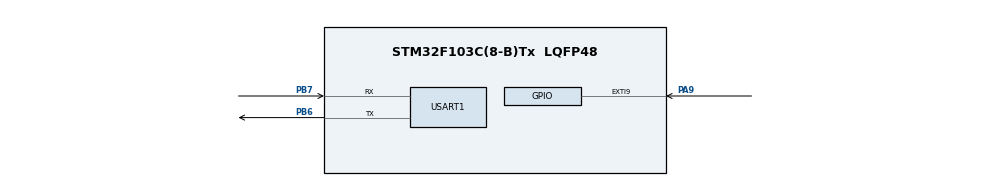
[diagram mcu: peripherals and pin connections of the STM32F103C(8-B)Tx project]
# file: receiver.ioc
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Mcu.Family=STM32F1
Mcu.Name=STM32F103C(8-B)Tx
Mcu.Package=LQFP48
NVIC.EXTI9_5_IRQn=true\:0\:0\:false\:false\:true\:true\:true\:true
NVIC.PriorityGroup=NVIC_PRIORITYGROUP_4
NVIC.TIM2_IRQn=true\:0\:0\:false\:false\:true\:true\:true\:true
PA13.Mode=Serial_Wire
PA13.Signal=SYS_JTMS-SWDIO
PA14.Mode=Serial_Wire
PA14.Signal=SYS_JTCK-SWCLK
PA9.GPIO_PuPd=GPIO_PULLUP
PA9.Signal=GPXTI9
PB6.Mode=Asynchronous
PB6.Signal=USART1_TX
PB7.Mode=Asynchronous
PB7.Signal=USART1_RX
ProjectManager.HeapSize=0x200
ProjectManager.StackSize=0x400
ProjectManager.TargetToolchain=MDK-ARM V5.32
RCC.APB1Freq_Value=8000000
RCC.APB2Freq_Value=8000000
TIM2.AutoReloadPreload=TIM_AUTORELOAD_PRELOAD_ENABLE
TIM2.Period=70-1
USART1.VirtualMode=VM_ASYNC
VP_TIM2_VS_ClockSourceINT.Mode=Internal
board=custom

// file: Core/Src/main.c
/* USER CODE BEGIN Header */
/**
  ******************************************************************************
  * @file           : main.c
  * @brief          : Main program body
  ******************************************************************************
  * @attention
  *
  * Copyright (c) 2025 STMicroelectronics.
  * All rights reserved.
  *
  * This software is licensed under terms that can be found in the LICENSE file
  * in the root directory of this software component.
  * If no LICENSE file comes with this software, it is provided AS-IS.
  *
  ******************************************************************************
  */
/* USER CODE END Header */
#include "main.h"

/* USER CODE BEGIN Includes */
#include "string.h"
#include "stdio.h"
/* USER CODE END Includes */

TIM_HandleTypeDef htim2;

UART_HandleTypeDef huart1;

/* USER CODE BEGIN PV */
uint8_t rev_data = 0;
uint8_t rev_bit_counter = 0;
uint8_t rev_byte = 0;
uint8_t rep_started = 0;
uint32_t decimal_value = 0;
char err[20];
/* USER CODE END PV */

void SystemClock_Config(void);
static void MX_GPIO_Init(void);
static void MX_TIM2_Init(void);
static void MX_USART1_UART_Init(void);

int main(void)
{

  /* MCU Configuration--------------------------------------------------------*/

  /* Reset of all peripherals, Initializes the Flash interface and the Systick. */
  HAL_Init();

  /* Configure the system clock */
  SystemClock_Config();

  /* Initialize all configured peripherals */
  MX_GPIO_Init();
  MX_TIM2_Init();
  MX_USART1_UART_Init();

  /* Infinite loop */
  while (1)
  {
		HAL_NVIC_EnableIRQ(EXTI9_5_IRQn);
  }
}

void SystemClock_Config(void)
{
  RCC_OscInitTypeDef RCC_OscInitStruct = {0};
  RCC_ClkInitTypeDef RCC_ClkInitStruct = {0};

  /** Initializes the RCC Oscillators according to the specified parameters
  * in the RCC_OscInitTypeDef structure.
  */
  RCC_OscInitStruct.OscillatorType = RCC_OSCILLATORTYPE_HSI;
  RCC_OscInitStruct.HSIState = RCC_HSI_ON;
  RCC_OscInitStruct.HSICalibrationValue = RCC_HSICALIBRATION_DEFAULT;
  RCC_OscInitStruct.PLL.PLLState = RCC_PLL_NONE;
  if (HAL_RCC_OscConfig(&RCC_OscInitStruct) != HAL_OK)
  {
    Error_Handler();
  }

  /** Initializes the CPU, AHB and APB buses clocks
  */
  RCC_ClkInitStruct.ClockType = RCC_CLOCKTYPE_HCLK|RCC_CLOCKTYPE_SYSCLK
                              |RCC_CLOCKTYPE_PCLK1|RCC_CLOCKTYPE_PCLK2;
  RCC_ClkInitStruct.SYSCLKSource = RCC_SYSCLKSOURCE_HSI;
  RCC_ClkInitStruct.AHBCLKDivider = RCC_SYSCLK_DIV1;
  RCC_ClkInitStruct.APB1CLKDivider = RCC_HCLK_DIV1;
  RCC_ClkInitStruct.APB2CLKDivider = RCC_HCLK_DIV1;

  if (HAL_RCC_ClockConfig(&RCC_ClkInitStruct, FLASH_LATENCY_0) != HAL_OK)
  {
    Error_Handler();
  }
}

static void MX_TIM2_Init(void)
{

  TIM_ClockConfigTypeDef sClockSourceConfig = {0};
  TIM_MasterConfigTypeDef sMasterConfig = {0};

  htim2.Instance = TIM2;
  htim2.Init.Prescaler = 0;
  htim2.Init.CounterMode = TIM_COUNTERMODE_UP;
  htim2.Init.Period = 70-1;
  htim2.Init.ClockDivision = TIM_CLOCKDIVISION_DIV1;
  htim2.Init.AutoReloadPreload = TIM_AUTORELOAD_PRELOAD_ENABLE;
  if (HAL_TIM_Base_Init(&htim2) != HAL_OK)
  {
    Error_Handler();
  }
  sClockSourceConfig.ClockSource = TIM_CLOCKSOURCE_INTERNAL;
  if (HAL_TIM_ConfigClockSource(&htim2, &sClockSourceConfig) != HAL_OK)
  {
    Error_Handler();
  }
  sMasterConfig.MasterOutputTrigger = TIM_TRGO_RESET;
  sMasterConfig.MasterSlaveMode = TIM_MASTERSLAVEMODE_DISABLE;
  if (HAL_TIMEx_MasterConfigSynchronization(&htim2, &sMasterConfig) != HAL_OK)
  {
    Error_Handler();
  }

}

static void MX_USART1_UART_Init(void)
{

  huart1.Instance = USART1;
  huart1.Init.BaudRate = 115200;
  huart1.Init.WordLength = UART_WORDLENGTH_8B;
  huart1.Init.StopBits = UART_STOPBITS_1;
  huart1.Init.Parity = UART_PARITY_NONE;
  huart1.Init.Mode = UART_MODE_TX_RX;
  huart1.Init.HwFlowCtl = UART_HWCONTROL_NONE;
  huart1.Init.OverSampling = UART_OVERSAMPLING_16;
  if (HAL_UART_Init(&huart1) != HAL_OK)
  {
    Error_Handler();
  }

}

static void MX_GPIO_Init(void)
{
  GPIO_InitTypeDef GPIO_InitStruct = {0};

  /* GPIO Ports Clock Enable */
  __HAL_RCC_GPIOA_CLK_ENABLE();
  __HAL_RCC_GPIOB_CLK_ENABLE();

  /*Configure GPIO pin : PA9 */
  GPIO_InitStruct.Pin = GPIO_PIN_9;
  GPIO_InitStruct.Mode = GPIO_MODE_IT_RISING;
  GPIO_InitStruct.Pull = GPIO_PULLUP;
  HAL_GPIO_Init(GPIOA, &GPIO_InitStruct);

  /* EXTI interrupt init*/
  HAL_NVIC_SetPriority(EXTI9_5_IRQn, 0, 0);
  HAL_NVIC_EnableIRQ(EXTI9_5_IRQn);

}

/* USER CODE BEGIN 4 */
void HAL_TIM_PeriodElapsedCallback(TIM_HandleTypeDef *htim)
{
  if(htim == &htim2 && rep_started)
  {
    if(rev_bit_counter == 0)
    {
      if(HAL_GPIO_ReadPin(GPIOA,GPIO_PIN_9) == GPIO_PIN_RESET)
      {
        __HAL_TIM_SET_AUTORELOAD(&htim2, 69);
        __HAL_TIM_SET_COUNTER(&htim2, 0);
        rev_bit_counter = 1;
      }
      else
      {
        rep_started = 0;
        HAL_TIM_Base_Stop_IT(&htim2);
      }
    }
    else if(rev_bit_counter <= 8)
    {
      uint8_t bit_value = HAL_GPIO_ReadPin(GPIOA,GPIO_PIN_9);
      rev_byte >>= 1;
      if(bit_value)
			{
        rev_byte |= 0x80;
				rev_bit_counter++;
			}
		}
    else
    {
      if(HAL_GPIO_ReadPin(GPIOA,GPIO_PIN_9) == GPIO_PIN_SET)
      {
        rev_data = rev_byte;
        decimal_value = (uint32_t)rev_byte;
        sprintf(err, "Received: %lu\r\n", decimal_value);
        HAL_UART_Transmit(&huart1, (uint8_t*)err, strlen(err), HAL_MAX_DELAY);
      }

      rep_started = 0;
      HAL_TIM_Base_Stop_IT(&htim2);
    }
  }
}
/* USER CODE END 4 */

void Error_Handler(void)
{
  __disable_irq();
  while (1)
  {
  }
}
